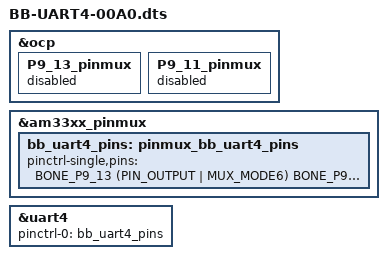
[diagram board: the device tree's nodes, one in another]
/*
 * Copyright (C) 2013 CircuitCo
 *
 * Virtual cape for UART4 on connector pins P9.13 P9.11
 *
 * This program is free software; you can redistribute it and/or modify
 * it under the terms of the GNU General Public License version 2 as
 * published by the Free Software Foundation.
 */

/dts-v1/;
/plugin/;

#include <dt-bindings/board/am335x-bbw-bbb-base.h>
#include <dt-bindings/pinctrl/am33xx.h>

/ {
	/*
	 * Free up the pins used by the cape from the pinmux helpers.
	 */
	fragment@0 {
		target = <&ocp>;
		__overlay__ {
			P9_13_pinmux { status = "disabled"; };	/* uart4_txd */
			P9_11_pinmux { status = "disabled"; };	/* uart4_rxd */
		};
	};

	fragment@1 {
		target = <&am33xx_pinmux>;
		__overlay__ {
			bb_uart4_pins: pinmux_bb_uart4_pins {
				pinctrl-single,pins = <
					BONE_P9_13 (PIN_OUTPUT | MUX_MODE6)	// gpmc_wpn.uart4_txd_mux2
					BONE_P9_11 (PIN_INPUT  | MUX_MODE6)	// gpmc_wait0.uart4_rxd_mux2
				>;
			};
		};
	};

	fragment@2 {
		target = <&uart4>;
		__overlay__ {
			status = "okay";
			pinctrl-names = "default";
			pinctrl-0 = <&bb_uart4_pins>;
		};
	};
};
